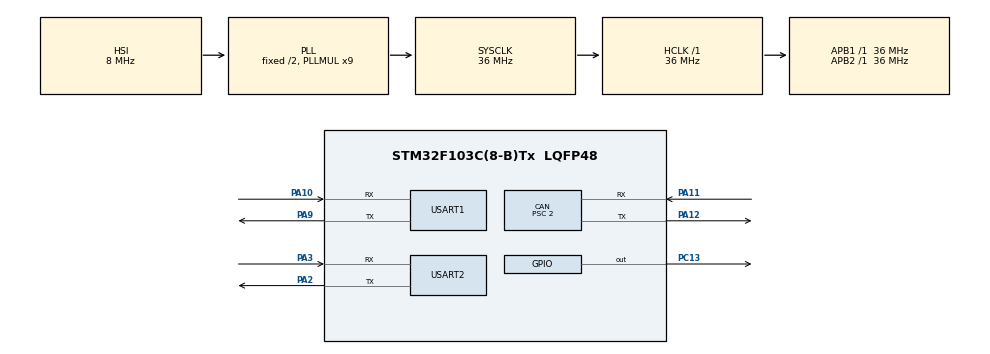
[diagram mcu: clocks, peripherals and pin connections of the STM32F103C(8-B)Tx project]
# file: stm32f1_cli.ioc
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CAN.ABOM=ENABLE
CAN.BS1=CAN_BS1_14TQ
CAN.BS2=CAN_BS2_3TQ
CAN.CalculateBaudRate=1000000
CAN.CalculateTimeBit=1000
CAN.CalculateTimeQuantum=55.55555555555556
CAN.NART=ENABLE
CAN.Prescaler=2
Mcu.Family=STM32F1
Mcu.Name=STM32F103C(8-B)Tx
Mcu.Package=LQFP48
NVIC.CAN1_SCE_IRQn=true\:5\:0\:true\:false\:true\:true\:true\:true
NVIC.PriorityGroup=NVIC_PRIORITYGROUP_4
NVIC.USART1_IRQn=true\:0\:0\:false\:false\:true\:true\:true\:true
NVIC.USART2_IRQn=true\:0\:0\:false\:false\:true\:true\:true\:true
NVIC.USB_HP_CAN1_TX_IRQn=true\:7\:0\:true\:false\:true\:true\:true\:true
NVIC.USB_LP_CAN1_RX0_IRQn=true\:6\:0\:true\:false\:true\:true\:true\:true
PA10.GPIO_PuPd=GPIO_PULLUP
PA10.Mode=Asynchronous
PA10.Signal=USART1_RX
PA11.Mode=CAN_Activate
PA11.Signal=CAN_RX
PA12.Mode=CAN_Activate
PA12.Signal=CAN_TX
PA13.Mode=Serial_Wire
PA13.Signal=SYS_JTMS-SWDIO
PA14.Mode=Serial_Wire
PA14.Signal=SYS_JTCK-SWCLK
PA2.Mode=Asynchronous
PA2.Signal=USART2_TX
PA3.GPIO_PuPd=GPIO_PULLUP
PA3.Mode=Asynchronous
PA3.Signal=USART2_RX
PA9.Mode=Asynchronous
PA9.Signal=USART1_TX
PC13-TAMPER-RTC.Signal=GPIO_Output
ProjectManager.HeapSize=0x200
ProjectManager.StackSize=0x400
ProjectManager.TargetToolchain=STM32CubeIDE
RCC.AHBFreq_Value=36000000
RCC.APB1Freq_Value=36000000
RCC.APB1TimFreq_Value=36000000
RCC.APB2Freq_Value=36000000
RCC.APB2TimFreq_Value=36000000
RCC.HCLKFreq_Value=36000000
RCC.PLLMUL=RCC_PLL_MUL9
RCC.SYSCLKFreq_VALUE=36000000
RCC.SYSCLKSource=RCC_SYSCLKSOURCE_PLLCLK
RCC.USBFreq_Value=36000000
USART1.VirtualMode=VM_ASYNC
USART2.VirtualMode=VM_ASYNC
board=custom

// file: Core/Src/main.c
/* USER CODE BEGIN Header */
/**
  ******************************************************************************
  * @file           : main.c
  * @brief          : Main program body
  ******************************************************************************
  * @attention
  *
  * Copyright (c) 2026 STMicroelectronics.
  * All rights reserved.
  *
  * This software is licensed under terms that can be found in the LICENSE file
  * in the root directory of this software component.
  * If no LICENSE file comes with this software, it is provided AS-IS.
  *
  ******************************************************************************
  */
/* USER CODE END Header */
#include "main.h"

/* USER CODE BEGIN Includes */
#include "app_main.h"
#include "hal_callbacks.h"
/* USER CODE END Includes */

CAN_HandleTypeDef hcan;

UART_HandleTypeDef huart1;
UART_HandleTypeDef huart2;

void SystemClock_Config(void);
static void MX_GPIO_Init(void);
static void MX_USART1_UART_Init(void);
static void MX_USART2_UART_Init(void);
static void MX_CAN_Init(void);

int main(void)
{

  /* MCU Configuration--------------------------------------------------------*/

  /* Reset of all peripherals, Initializes the Flash interface and the Systick. */
  HAL_Init();

  /* Configure the system clock */
  SystemClock_Config();

  /* Initialize all configured peripherals */
  MX_GPIO_Init();
  MX_USART1_UART_Init();
  MX_USART2_UART_Init();
  MX_CAN_Init();
  /* USER CODE BEGIN 2 */
  app_main_init();
  hal_callbacks_init();
  app_main_start();
  /* USER CODE END 2 */

  /* Infinite loop */
  while (1)
  {

  }
}

void SystemClock_Config(void)
{
  RCC_OscInitTypeDef RCC_OscInitStruct = {0};
  RCC_ClkInitTypeDef RCC_ClkInitStruct = {0};

  /** Initializes the RCC Oscillators according to the specified parameters
  * in the RCC_OscInitTypeDef structure.
  */
  RCC_OscInitStruct.OscillatorType = RCC_OSCILLATORTYPE_HSI;
  RCC_OscInitStruct.HSIState = RCC_HSI_ON;
  RCC_OscInitStruct.HSICalibrationValue = RCC_HSICALIBRATION_DEFAULT;
  RCC_OscInitStruct.PLL.PLLState = RCC_PLL_ON;
  RCC_OscInitStruct.PLL.PLLSource = RCC_PLLSOURCE_HSI_DIV2;
  RCC_OscInitStruct.PLL.PLLMUL = RCC_PLL_MUL9;
  if (HAL_RCC_OscConfig(&RCC_OscInitStruct) != HAL_OK)
  {
    Error_Handler();
  }

  /** Initializes the CPU, AHB and APB buses clocks
  */
  RCC_ClkInitStruct.ClockType = RCC_CLOCKTYPE_HCLK|RCC_CLOCKTYPE_SYSCLK
                              |RCC_CLOCKTYPE_PCLK1|RCC_CLOCKTYPE_PCLK2;
  RCC_ClkInitStruct.SYSCLKSource = RCC_SYSCLKSOURCE_PLLCLK;
  RCC_ClkInitStruct.AHBCLKDivider = RCC_SYSCLK_DIV1;
  RCC_ClkInitStruct.APB1CLKDivider = RCC_HCLK_DIV1;
  RCC_ClkInitStruct.APB2CLKDivider = RCC_HCLK_DIV1;

  if (HAL_RCC_ClockConfig(&RCC_ClkInitStruct, FLASH_LATENCY_1) != HAL_OK)
  {
    Error_Handler();
  }
}

static void MX_CAN_Init(void)
{

  hcan.Instance = CAN1;
  hcan.Init.Prescaler = 2;
  hcan.Init.Mode = CAN_MODE_NORMAL;
  hcan.Init.SyncJumpWidth = CAN_SJW_1TQ;
  hcan.Init.TimeSeg1 = CAN_BS1_14TQ;
  hcan.Init.TimeSeg2 = CAN_BS2_3TQ;
  hcan.Init.TimeTriggeredMode = DISABLE;
  hcan.Init.AutoBusOff = ENABLE;
  hcan.Init.AutoWakeUp = DISABLE;
  hcan.Init.AutoRetransmission = ENABLE;
  hcan.Init.ReceiveFifoLocked = DISABLE;
  hcan.Init.TransmitFifoPriority = DISABLE;
  if (HAL_CAN_Init(&hcan) != HAL_OK)
  {
    Error_Handler();
  }

}

static void MX_USART1_UART_Init(void)
{

  huart1.Instance = USART1;
  huart1.Init.BaudRate = 115200;
  huart1.Init.WordLength = UART_WORDLENGTH_8B;
  huart1.Init.StopBits = UART_STOPBITS_1;
  huart1.Init.Parity = UART_PARITY_NONE;
  huart1.Init.Mode = UART_MODE_TX_RX;
  huart1.Init.HwFlowCtl = UART_HWCONTROL_NONE;
  huart1.Init.OverSampling = UART_OVERSAMPLING_16;
  if (HAL_UART_Init(&huart1) != HAL_OK)
  {
    Error_Handler();
  }

}

static void MX_USART2_UART_Init(void)
{

  huart2.Instance = USART2;
  huart2.Init.BaudRate = 115200;
  huart2.Init.WordLength = UART_WORDLENGTH_8B;
  huart2.Init.StopBits = UART_STOPBITS_1;
  huart2.Init.Parity = UART_PARITY_NONE;
  huart2.Init.Mode = UART_MODE_TX_RX;
  huart2.Init.HwFlowCtl = UART_HWCONTROL_NONE;
  huart2.Init.OverSampling = UART_OVERSAMPLING_16;
  if (HAL_UART_Init(&huart2) != HAL_OK)
  {
    Error_Handler();
  }

}

static void MX_GPIO_Init(void)
{
  GPIO_InitTypeDef GPIO_InitStruct = {0};

  /* GPIO Ports Clock Enable */
  __HAL_RCC_GPIOC_CLK_ENABLE();
  __HAL_RCC_GPIOA_CLK_ENABLE();

  /*Configure GPIO pin Output Level */
  HAL_GPIO_WritePin(GPIOC, GPIO_PIN_13, GPIO_PIN_RESET);

  /*Configure GPIO pin : PC13 */
  GPIO_InitStruct.Pin = GPIO_PIN_13;
  GPIO_InitStruct.Mode = GPIO_MODE_OUTPUT_PP;
  GPIO_InitStruct.Pull = GPIO_NOPULL;
  GPIO_InitStruct.Speed = GPIO_SPEED_FREQ_LOW;
  HAL_GPIO_Init(GPIOC, &GPIO_InitStruct);

}

void Error_Handler(void)
{
  __disable_irq();
  while (1)
  {
  }
}
